# M06_ClockManager register map
Vendor: Babel; File version: 1.0
M06_ClockManager Register Map
CPU: CM0 r0p0, little endian, no MPU, no FPU
Registers are 32-bit, read-write, reset 0x0 unless marked. A register's access mark holds for its fields unless they carry their own. Offsets are from the block's base; lines under a group give offsets from that group; [hi:lo] are bit positions; {n}, {i} and the like mark numbered series; 'fields as' and 'values as' point back to an identical list; <NAME> marks a mode.

## Memory map
0x00000000 M06_ClockManager

## M06_ClockManager
Base 0x00000000
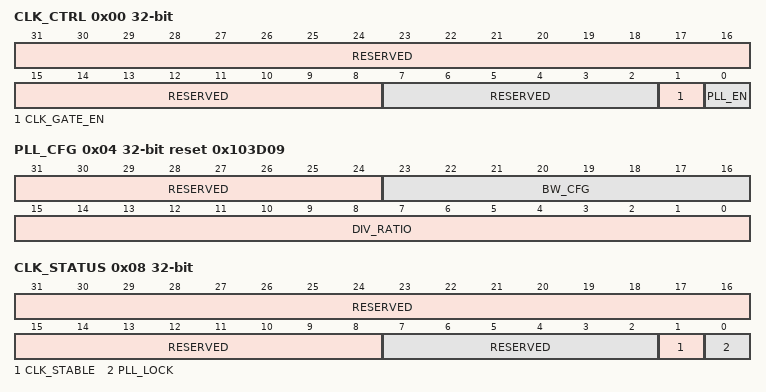
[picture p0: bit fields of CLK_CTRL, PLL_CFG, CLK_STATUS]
0x00 CLK_CTRL — 时钟控制：PLL 使能、时钟门控
  [31:8] RESERVED - — 保留，必须写 0
  [7:2] RESERVED - — 保留，必须写 0
  [1] CLK_GATE_EN — 时钟门控使能。1=使能，0=禁用
  [0] PLL_EN — PLL 使能。1=使能，0=禁用
0x04 PLL_CFG reset 0x103D09 — PLL 配置：倍频系数、环路带宽
  [31:24] RESERVED - — 保留，必须写 0
  [23:16] BW_CFG — 环路带宽配置
  [15:0] DIV_RATIO — PLL 倍频系数（15625 = 500MHz/32kHz）
0x08 CLK_STATUS ro — 时钟状态：PLL 锁定、时钟稳定
  [31:8] RESERVED - — 保留
  [7:2] RESERVED - — 保留
  [1] CLK_STABLE — 时钟稳定指示。1=时钟输出稳定
  [0] PLL_LOCK — PLL 锁定状态。1=已锁定
